# ISD91200B_v1 register map
File version: 1.0
Registers are 32-bit, read-write, reset 0x0 unless marked. A register's access mark holds for its fields unless they carry their own. Offsets are from the block's base; [hi:lo] are bit positions; {n}, {i} and the like mark numbered series; 'fields as' and 'values as' point back to an identical list.

## SDADC — SDADC Register Map
Base 0x400E0000
0x00 SDADC_DAT ro reset not defined — SD ADC FIFO Data Read Register
  [15:0] RESULT — Delta-Sigma ADC DATA FIFO Read. A read of this register will read data from the audio FIFO and increment the read pointer. A read past empty will repeat the last data. Can be used with SDADC_FIFOSTS.THIF to determine if valid data is present in FIFO.
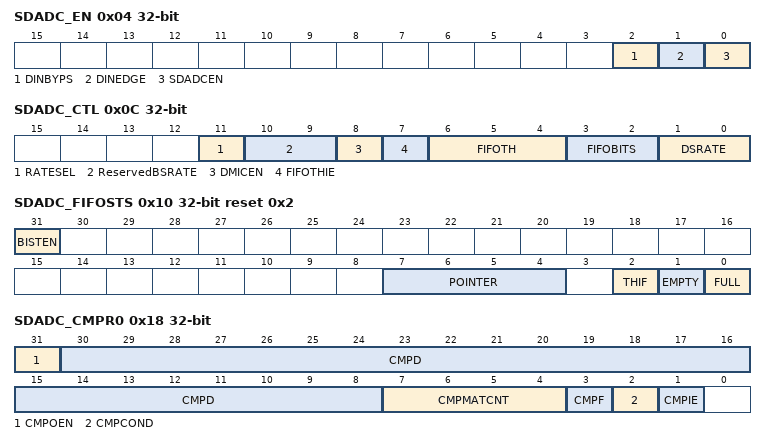
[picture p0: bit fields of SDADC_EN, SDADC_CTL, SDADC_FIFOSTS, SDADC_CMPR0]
0x04 SDADC_EN — SD ADC Enable Register
  [2] DINBYPS — ADC data input bypass (internal debug)
    0=normal mode; 1=analog 5bits to FIFO for testing
  [1] DINEDGE — ADC data input clock edge selection
    0=ADC clock negetive edge latch; 1=ADC clock positive edge latch
  [0] SDADCEN — SDADC Enable
    0=Conversion stopped and ADC is reset including FIFO pointers; 1=ADC Conversion enabled
0x08 SDADC_CLKDIV — SD ADC Clock Divider Register
  [7:0] CLKDIV — SD_CLK Clock Divider. SDADC internal clock divider. CLKDIV should be set to give a SD_CLK frequency in the range of 1.024-6.144MHz. (Refer to 7.1.4.2.). CLKDIV must be greater than and equal 2.
0x0C SDADC_CTL — SD ADC Control Register
  [11] RATESEL — Sample Rate Selection
    0=choose DSRATE for SDADC; 1=choose BSRATE for BS
  [10:9] ReservedBSRATE — Down Sampling for BS
    0=down sample 2000 for SPS384; 1=down sampel 4000(reserved); 2=down sample 8000(reserved); 3=down sample 16000 for SPS9.6,SPS19.2,SPS38.4 and SPS76.8Reserved
  [8] DMICEN — Digital MIC Enable
    0=keep SDADC function; 1=turn digital MIC function input from GPIO
  [7] FIFOTHIE — FIFO Threshold Interrupt Enable
    0=disable interrupt whenever FIFO level exceeds that set in FIFOTH; 1=enable interrupt whenever FIFO level exceeds that set in FIFOTH
  [6:4] FIFOTH — FIFO Threshold: Determines at what level the ADC FIFO will generate a interrupt. Interrupt will be generated when number of words present in ADC FIFO is > FIFOTH.
  [3:2] FIFOBITS — FIFO Data Bits Selection
    0=32 bits; 1=16 bits; 2=8 bits; 3=24 bits
  [1:0] DSRATE — Down Sampling Ratio
    1=down sample X 16; 2=down sample X 32; 3=down sample X 64
0x10 SDADC_FIFOSTS reset 0x2 — SD ADC FIFO Status Register
  [31] BISTEN — BIST Enable. Internal use
    0=Disable SDADC FIFO BIST testing; 1=Enable SDADC FIFO BIST testing SDADC FIFO can be testing by Cortex-M0
  [7:4] POINTER ro — SDADC FIFO Pointer (Read Only). The FULL bit and POINTER[3:0] indicates the field that the valid data count within the SDADC FIFO buffer. The Maximum value shown in POINTER is 15. When the using level of SDADC FIFO Buffer equal to 16, The FULL bit is set to 1.
  [2] THIF ro — ADC FIFO Threshold Interrupt Status (Read Only)
    0=The valid data count within the transmit FIFO buffer is less than to the setting value of FIFOTH; 1=The valid data count within the SDADC FIFO buffer is larger than or equal the setting value of FIFOTH
  [1] EMPTY — FIFO Empty
    0=FIFO is not empty; 1=FIFO is empty
  [0] FULL — FIFO Full
    0=FIFO is not full; 1=FIFO is full
0x14 SDADC_PDMACTL — SD ADC PDMA Control Register
  [0] PDMAEN — Enable SDADC PDMA Receive Channel
    0=Disable SDADC PDMA; 1=Enable SDADC PDMA
0x18 SDADC_CMPR0 — SD ADC Comparator 0 Control Register
  [31] CMPOEN — Compare Match output FIFO zero
    0=FIFO data keep original one; 1=compare match then FIFO out zero
  [30:8] CMPD — Comparison Data. 23 bit value to compare to FIFO output word.
  [7:4] CMPMATCNT — Compare Match Count. When the A/D FIFO result matches the compare condition defined by CMPCOND, the internal match counter will increase by 1. When the internal counter reaches the value to (CMPMATCNT +1), the CMPF bit will be set.
  [3] CMPF — Compare Flag. When the conversion result meets condition in CMPCOND and CMPMATCNT this bit is set to 1. It is cleared by writing 1 to self.
  [2] CMPCOND — Compare Condition. Note: When the internal counter reaches the value (CMPMATCNT +1), the CMPF bit will be set.
    0=Set the compare condition that result is less than CMPD; 1=Set the compare condition that result is greater or equal to CMPD
  [1] CMPIE — Compare Interrupt Enable. If the compare function is enabled and the compare condition matches the setting of CMPCOND and CMPMATCNT, CMPF bit will be asserted, if CMPIE is set to 1, a compare interrupt request is generated.
    0=Disable compare function interrupt; 1=Enable compare function interrupt
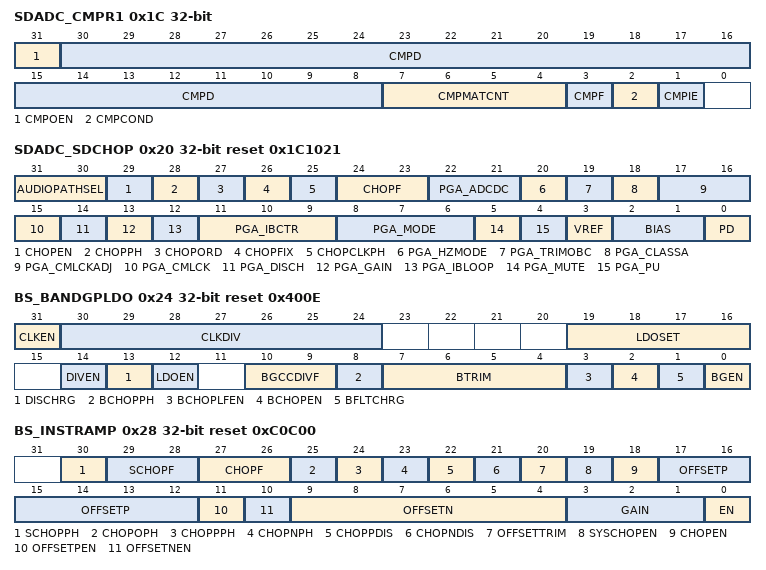
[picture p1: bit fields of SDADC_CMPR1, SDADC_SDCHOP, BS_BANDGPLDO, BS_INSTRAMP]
0x1C SDADC_CMPR1 — SD ADC Comparator 1 Control Register
  fields as SDADC_CMPR0
0x20 SDADC_SDCHOP reset 0x1C1021 — Sigma Delta Analog Block Control Register
  [31:30] AUDIOPATHSEL — Audio Path Selection, Connect SDADC input to
    2=Bridge Sense
  [29] CHOPEN — SDADC chopper enable
    0=disable (default); 1=enable
  [28] CHOPPH — SDADC chopper phase. When chopper is off:
    0=chopper switches in default state; 1=invert chopper switches
  [27] CHOPORD — SDADC Chopper Order
    0=1st order dithering of chopper frequency (default); 1=2nd order dithering of chopper frequency
  [26] CHOPFIX — SDADC Chopper Fixed Frequency
    0=dither chopper frequency (default); 1=choose fixed frequency
  [25] CHOPCLKPH — SDADC Chopper Clock phase selection
    0=chopper transition after falling edge of ADC_CLK (default); 1=chopper transition after rising edge of ADC_CLK
  [24:23] CHOPF — SDADC Chopper Frequency in fixed chop mode
    0=Fs/2 (default); 1=Fs/4; 2=Fs/8; 3=Fs/16
  [22:21] PGA_ADCDC
    0=Default
  [20] PGA_HZMODE — Select input impedance
    0=12k Ohm input impedance; 1=500k Ohm input impedance (default)
  [19] PGA_TRIMOBC — Trim current in output driver
    0=disable; 1=enable (default)
  [18] PGA_CLASSA — Enable Class A mode of operation
    0=Class AB; 1=Class A (default)
  [17:16] PGA_CMLCKADJ
  [15] PGA_CMLCK — Common mode Threshold lock adjust enable
    0=Enable; 1=Disable
  [14] PGA_DISCH — Charge inputs selected by PGA_ACDC[1:0] to VREF
    0=Disable; 1=Enable
  [13] PGA_GAIN
  [12] PGA_IBLOOP — Trim PGA current
    1=default
  [11:9] PGA_IBCTR — Trim PGA Current
    0=default
  [8:6] PGA_MODE — PGA mode selection;
    0=Disable; 1=Enable
  [5] PGA_MUTE — Mute control signal. 0—disable. 1—enable
  [4] PGA_PU — Power up PGA. 0—disable. 1—enable
  [3] VREF — SDADC Chopper in Reference Buffer
    0=chopper off; 1=chopper on
  [2:1] BIAS — SDADC Bias Current Selection
    0=1; 1=0.75; 2=0.5; 3=1.25
  [0] PD — SDADC Power Down
    0=SDADC power on; 1=SDADC power off
0x24 BS_BANDGPLDO reset 0x400E — Bridge Sense Bandgap and LDO Control Register
  [31] CLKEN — Bridge Sense clock enable for 400KHz, 200KHz and 160Hz
    0=disable; 1=enable
  [30:24] CLKDIV — Bridge Sense clock divider for 400KHz. ADC_CLK /(2*400K)
  [19:16] LDOSET — BS set LDO output voltage
    0=1.5; 1=1.8; 2=2.1; 3=2.4; 4=2.7; 5=3.0; 6=3.3; 7=3.6; 8=3.9; 9=4.2; 10=4.5
  [14] DIVEN — BS LDO Voltage Divider Enable
    0=disable; 1=enable
  [13] DISCHRG — BS LDO Discharge
    0=disable; 1=enable
  [12] LDOEN — BS LDO(Bridge Bias) Enable
    0=disable; 1=enable
  [10:9] BGCCDIVF — BS Bandgap Lf chopper frequency selection
    0=1024; 1=512; 2=256; 3=128
  [8] BCHOPPH — BS Bandgap chopper phase. When chopper is off
    values as SDADC_SDCHOP.CHOPPH
  [7:4] BTRIM — BS Bandgap TRIM
    0=bandgap +0; {v}=bandgap+({v}*12)mV (v=1..7); 8=bandgap-(8*12)mV; 9=bandgap-(7*12)mV; 10=bandgap-(6*12)mV; 11=bandgap-(5*12)mV; 12=bandgap-(4*12)mV; 13=bandgap-(3*12)mV; 14=bandgap-(2*12)mV; 15=bandgap-(1*12)mV
  [3] BCHOPLFEN — BS Bandgap low frequency chopper enable
    0=disable; 1=enable
  [2] BCHOPEN — BS Bandgap chopper enable
    0=disable; 1=enable
  [1] BFLTCHRG — BS Bandgap filter charge
    0=high impedance mode (low noise); 1=quick charge external capacitor
  [0] BGEN — BS Bandgap enable
    0=disable; 1=enable
0x28 BS_INSTRAMP reset 0xC0C00 — Bridge Sense Instrumentation Amplifer Control Register
  [30] SCHOPPH — BS Instrumentation Amplifer System chopper phase. When system chopper is off
    0=system chopper switches in default state; 1=invert system chopper switches
  [29:28] SCHOPF — BS Instrumentation Amplifer System chopper frequency
    0=40Hz; 1=80Hz; 2=20Hz; 3=10Hz
  [27:26] CHOPF — BS Instrumentation Amplifer chopper frequency selection
    0=100kHz; 1=200kHz; 2=50kHz; 3=25kHz
  [25] CHOPOPH — BS Instrumentation Amplifer chopper phase output opamp. When chopper is off
    0=chopper switches in output opamp in default state; 1=invert chopper switches in output opamp
  [24] CHOPPPH — BS Instrumentation Amplifer chopper phase positive input opamp. When chopper is off or when OFFSETTRIM bit is high
    0=chopper switches in positive input opamp in default state; 1=invert chopper switches in positive input opamp
  [23] CHOPNPH — BS Instrumentation Amplifer chopper phase negative input opamp. When chopper is off or when OFFSETTRIM bit is high
    0=chopper switches in negative input opamp in default state; 1=invert chopper switches in negative input opamp
  [22] CHOPPDIS — BS Instrumentation Amplifer chopper positive disable. When OFFSETTRIM bit is high
    0=Enable chopper in positive input opamp; 1=disable chopper in positive input opamp
  [21] CHOPNDIS — BS Instrumentation Amplifer chopper negative disable. When OFFSETTRIM bit is high
    0=Enable chopper in negative input opamp; 1=disable chopper in negative input opamp
  [20] OFFSETTRIM — BS Instrumentation Amplifer offset trim mode
    0=disable offset trim mode; 1=enable offset trim mode
  [19] SYSCHOPEN — BS Instrumentation Amplifer system chopper enable
    0=disable system chopper; 1=enable system chopper
  [18] CHOPEN — BS Instrumentation Amplifer chopper enable
    0=disable choppers in the three opamps; 1=enable choppers in the three opamps
  [17:12] OFFSETP — BS Instrumentation Amplifer offset positive input opamp
  [11] OFFSETPEN — BS Instrumentation Amplifer offset positive input opamp enable
    0=don't use bits [17:12]; 1=use value of bits [17:12] to change offset of positive input opamp
  [10] OFFSETNEN — BS Instrumentation Amplifer offset negetvie input opamp enable
    0=don't use bits [9:4]; 1=use value of bits [9:4] to change offset of positive input opamp
  [9:4] OFFSETN — BS Instrumentation Amplifer offset negetive input opamp
  [3:1] GAIN — BS Instrumentation Amplifer GAIN
    0=1; 1=2; 2=4; 3=8; 4=16; 5=32; 6=64; 7=128
  [0] EN — BS Instrumentation Amplifer enable
    0=Disable; 1=Enable
